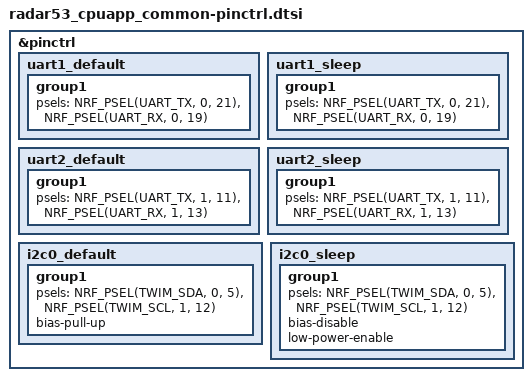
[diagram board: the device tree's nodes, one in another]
&pinctrl {
	uart1_default: uart1_default {
		group1 {
		psels = <NRF_PSEL(UART_TX, 0, 21)>,<NRF_PSEL(UART_RX, 0, 19)>;
		};
	};
	uart1_sleep: uart1_sleep {
	  group1 {
		psels = <NRF_PSEL(UART_TX, 0, 21)>,<NRF_PSEL(UART_RX, 0, 19)>;
	  };
	};

	uart2_default: uart2_default {
		group1 {
		psels = <NRF_PSEL(UART_TX, 1, 11)>,<NRF_PSEL(UART_RX, 1, 13)>;
		};
	};
	uart2_sleep: uart2_sleep {
	  group1 {
		psels = <NRF_PSEL(UART_TX, 1, 11)>,<NRF_PSEL(UART_RX, 1, 13)>;
	  };
	};

	i2c0_default: i2c0_default {
		group1 {
			psels = <NRF_PSEL(TWIM_SDA, 0, 5)>,<NRF_PSEL(TWIM_SCL, 1, 12)>;
			bias-pull-up;
		};
	};

	i2c0_sleep: i2c0_sleep {
		group1 {
			psels = <NRF_PSEL(TWIM_SDA, 0, 5)>,<NRF_PSEL(TWIM_SCL, 1, 12)>;
			bias-disable;
			low-power-enable;
		};
	};
};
